# iostr710 register map
Registers are 16-bit, access not given, no defined reset value unless marked. A register's access mark holds for its fields unless they carry their own. Addresses are absolute; registers are grouped by the start of their names; [hi:lo] are bit positions; {n}, {i} and the like mark numbered series.

## I2C0
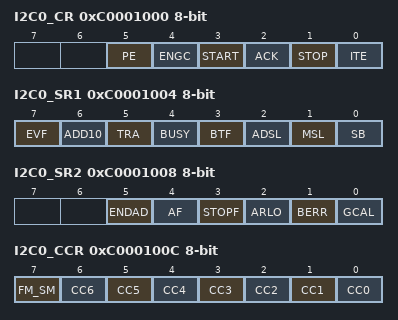
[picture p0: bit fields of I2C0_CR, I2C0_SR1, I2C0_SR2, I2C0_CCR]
0xC0001000 I2C0_CR 8-bit
  [5] PE, [4] ENGC, [3] START, [2] ACK, [1] STOP, [0] ITE
0xC0001004 I2C0_SR1 8-bit
  [7] EVF, [6] ADD10, [5] TRA, [4] BUSY, [3] BTF, [2] ADSL, [1] MSL, [0] SB
0xC0001008 I2C0_SR2 8-bit
  [5] ENDAD, [4] AF, [3] STOPF, [2] ARLO, [1] BERR, [0] GCAL
0xC000100C I2C0_CCR 8-bit
  [7] FM_SM, [n] CC{n} (n=0..6)
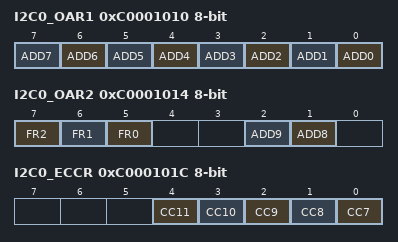
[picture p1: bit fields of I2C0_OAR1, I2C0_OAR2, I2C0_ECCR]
0xC0001010 I2C0_OAR1 8-bit
  [n] ADD{n} (n=0..7)
0xC0001014 I2C0_OAR2 8-bit
  [7] FR2, [6] FR1, [5] FR0, [2] ADD9, [1] ADD8
0xC0001018 I2C0_DR 8-bit
0xC000101C I2C0_ECCR 8-bit
  [n-7] CC{n} (n=7..11)

## I2C1
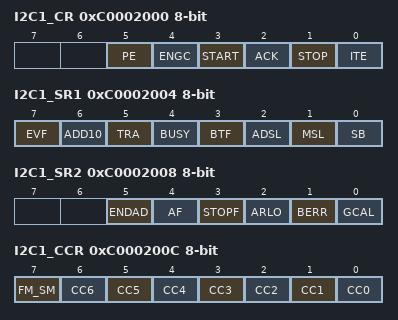
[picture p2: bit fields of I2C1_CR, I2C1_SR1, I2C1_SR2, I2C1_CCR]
0xC0002000 I2C1_CR 8-bit
  [5] PE, [4] ENGC, [3] START, [2] ACK, [1] STOP, [0] ITE
0xC0002004 I2C1_SR1 8-bit
  [7] EVF, [6] ADD10, [5] TRA, [4] BUSY, [3] BTF, [2] ADSL, [1] MSL, [0] SB
0xC0002008 I2C1_SR2 8-bit
  [5] ENDAD, [4] AF, [3] STOPF, [2] ARLO, [1] BERR, [0] GCAL
0xC000200C I2C1_CCR 8-bit
  [7] FM_SM, [n] CC{n} (n=0..6)
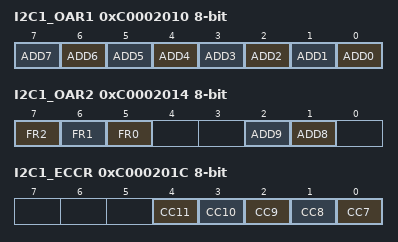
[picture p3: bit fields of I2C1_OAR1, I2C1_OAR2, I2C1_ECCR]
0xC0002010 I2C1_OAR1 8-bit
  [n] ADD{n} (n=0..7)
0xC0002014 I2C1_OAR2 8-bit
  [7] FR2, [6] FR1, [5] FR0, [2] ADD9, [1] ADD8
0xC0002018 I2C1_DR 8-bit
0xC000201C I2C1_ECCR 8-bit
  [n-7] CC{n} (n=7..11)

## BSPI0
0xC000A000 BSPI0_RXR
  [15:8] RX_8BITS
0xC000A004 BSPI0_TXR
  [15:8] TX_8BITS
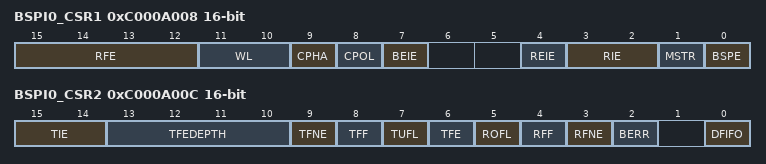
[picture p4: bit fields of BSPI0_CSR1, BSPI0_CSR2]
0xC000A008 BSPI0_CSR1
  [15:12] RFE, [11:10] WL, [9] CPHA, [8] CPOL, [7] BEIE, [4] REIE, [3:2] RIE, [1] MSTR, [0] BSPE
0xC000A00C BSPI0_CSR2
  [15:14] TIE, [13:10] TFEDEPTH, [9] TFNE, [8] TFF, [7] TUFL, [6] TFE, [5] ROFL, [4] RFF, [3] RFNE, [2] BERR, [0] DFIFO
0xC000A010 BSPI0_CLK 8-bit

## BSPI1
0xC000B000 BSPI1_RXR
  [15:8] RX_8BITS
0xC000B004 BSPI1_TXR
  [15:8] TX_8BITS
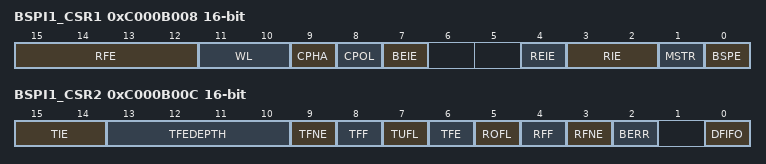
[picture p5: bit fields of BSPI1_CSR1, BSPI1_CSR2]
0xC000B008 BSPI1_CSR1
  [15:12] RFE, [11:10] WL, [9] CPHA, [8] CPOL, [7] BEIE, [4] REIE, [3:2] RIE, [1] MSTR, [0] BSPE
0xC000B00C BSPI1_CSR2
  [15:14] TIE, [13:10] TFEDEPTH, [9] TFNE, [8] TFF, [7] TUFL, [6] TFE, [5] ROFL, [4] RFF, [3] RFNE, [2] BERR, [0] DFIFO
0xC000B010 BSPI1_CLK 8-bit

## UART0
0xC0004000 UART0_BR
0xC0004004 UART0_TXBUFR
  [8:0] TX
0xC0004008 UART0_RXBUFR
  [9:0] RX
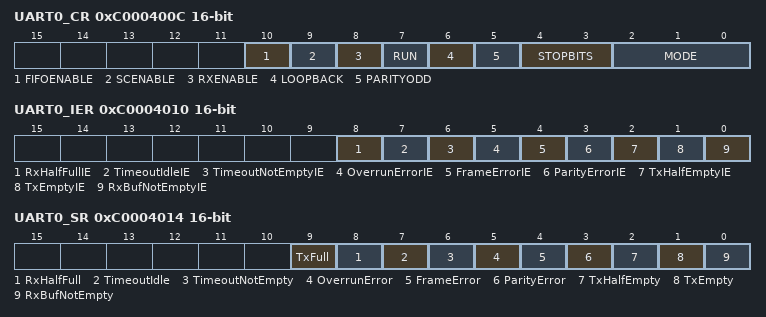
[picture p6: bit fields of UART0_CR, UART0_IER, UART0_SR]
0xC000400C UART0_CR
  [10] FIFOENABLE, [9] SCENABLE, [8] RXENABLE, [7] RUN, [6] LOOPBACK, [5] PARITYODD, [4:3] STOPBITS, [2:0] MODE
0xC0004010 UART0_IER
  [8] RxHalfFullIE, [7] TimeoutIdleIE, [6] TimeoutNotEmptyIE, [5] OverrunErrorIE, [4] FrameErrorIE, [3] ParityErrorIE, [2] TxHalfEmptyIE, [1] TxEmptyIE, [0] RxBufNotEmptyIE
0xC0004014 UART0_SR
  [9] TxFull, [8] RxHalfFull, [7] TimeoutIdle, [6] TimeoutNotEmpty, [5] OverrunError, [4] FrameError, [3] ParityError, [2] TxHalfEmpty, [1] TxEmpty, [0] RxBufNotEmpty
0xC0004018 UART0_GTR
  [7:0] GUARDTIME
0xC000401C UART0_TOR
  [7:0] TIMEOUT
0xC0004020 UART0_TXRSTR
0xC0004024 UART0_RXRSTR

## UART1
0xC0005000 UART1_BR
0xC0005004 UART1_TXBUFR
  [8:0] TX
0xC0005008 UART1_RXBUFR
  [9:0] RX
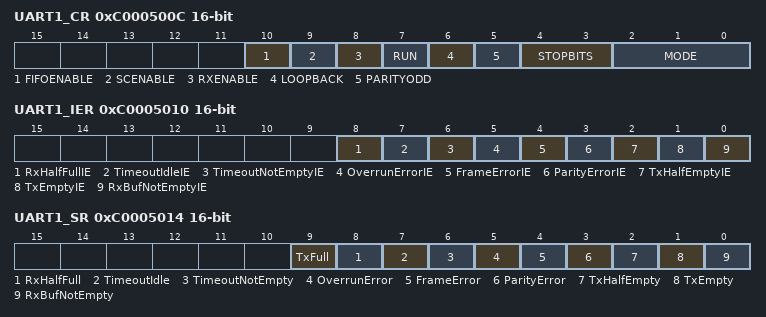
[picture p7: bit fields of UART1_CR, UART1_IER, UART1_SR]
0xC000500C UART1_CR
  [10] FIFOENABLE, [9] SCENABLE, [8] RXENABLE, [7] RUN, [6] LOOPBACK, [5] PARITYODD, [4:3] STOPBITS, [2:0] MODE
0xC0005010 UART1_IER
  [8] RxHalfFullIE, [7] TimeoutIdleIE, [6] TimeoutNotEmptyIE, [5] OverrunErrorIE, [4] FrameErrorIE, [3] ParityErrorIE, [2] TxHalfEmptyIE, [1] TxEmptyIE, [0] RxBufNotEmptyIE
0xC0005014 UART1_SR
  [9] TxFull, [8] RxHalfFull, [7] TimeoutIdle, [6] TimeoutNotEmpty, [5] OverrunError, [4] FrameError, [3] ParityError, [2] TxHalfEmpty, [1] TxEmpty, [0] RxBufNotEmpty
0xC0005018 UART1_GTR
  [7:0] GUARDTIME
0xC000501C UART1_TOR
  [7:0] TIMEOUT
0xC0005020 UART1_TXRSTR
0xC0005024 UART1_RXRSTR

## SC
0xC0005040 SC_CLKVAL
  [4:0] SCCLKVAL
0xC0005044 SC_CLKCON
  [0] EN

## UART2
0xC0006000 UART2_BR
0xC0006004 UART2_TXBUFR
  [8:0] TX
0xC0006008 UART2_RXBUFR
  [9:0] RX
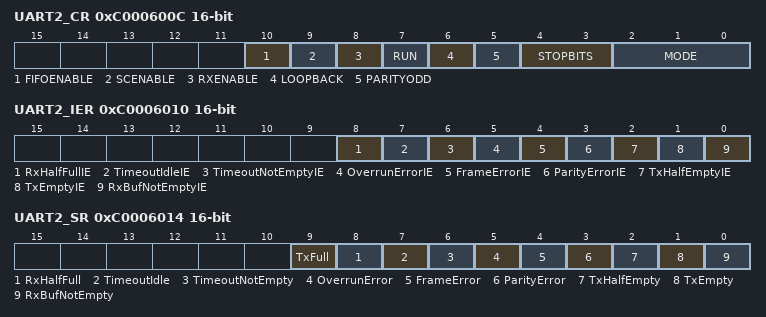
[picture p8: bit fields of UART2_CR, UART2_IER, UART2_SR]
0xC000600C UART2_CR
  [10] FIFOENABLE, [9] SCENABLE, [8] RXENABLE, [7] RUN, [6] LOOPBACK, [5] PARITYODD, [4:3] STOPBITS, [2:0] MODE
0xC0006010 UART2_IER
  [8] RxHalfFullIE, [7] TimeoutIdleIE, [6] TimeoutNotEmptyIE, [5] OverrunErrorIE, [4] FrameErrorIE, [3] ParityErrorIE, [2] TxHalfEmptyIE, [1] TxEmptyIE, [0] RxBufNotEmptyIE
0xC0006014 UART2_SR
  [9] TxFull, [8] RxHalfFull, [7] TimeoutIdle, [6] TimeoutNotEmpty, [5] OverrunError, [4] FrameError, [3] ParityError, [2] TxHalfEmpty, [1] TxEmpty, [0] RxBufNotEmpty
0xC0006018 UART2_GTR
  [7:0] GUARDTIME
0xC000601C UART2_TOR
  [7:0] TIMEOUT
0xC0006020 UART2_TXRSTR
0xC0006024 UART2_RXRSTR

## UART3
0xC0007000 UART3_BR
0xC0007004 UART3_TXBUFR
  [8:0] TX
0xC0007008 UART3_RXBUFR
  [9:0] RX
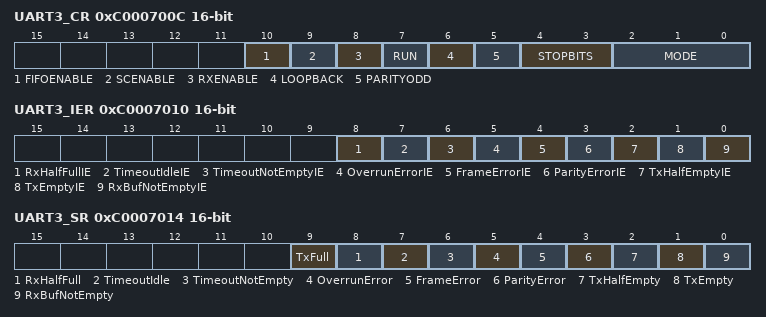
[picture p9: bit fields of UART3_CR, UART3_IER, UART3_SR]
0xC000700C UART3_CR
  [10] FIFOENABLE, [9] SCENABLE, [8] RXENABLE, [7] RUN, [6] LOOPBACK, [5] PARITYODD, [4:3] STOPBITS, [2:0] MODE
0xC0007010 UART3_IER
  [8] RxHalfFullIE, [7] TimeoutIdleIE, [6] TimeoutNotEmptyIE, [5] OverrunErrorIE, [4] FrameErrorIE, [3] ParityErrorIE, [2] TxHalfEmptyIE, [1] TxEmptyIE, [0] RxBufNotEmptyIE
0xC0007014 UART3_SR
  [9] TxFull, [8] RxHalfFull, [7] TimeoutIdle, [6] TimeoutNotEmpty, [5] OverrunError, [4] FrameError, [3] ParityError, [2] TxHalfEmpty, [1] TxEmpty, [0] RxBufNotEmpty
0xC0007018 UART3_GTR
  [7:0] GUARDTIME
0xC000701C UART3_TOR
  [7:0] TIMEOUT
0xC0007020 UART3_TXRSTR
0xC0007024 UART3_RXRSTR

## USB
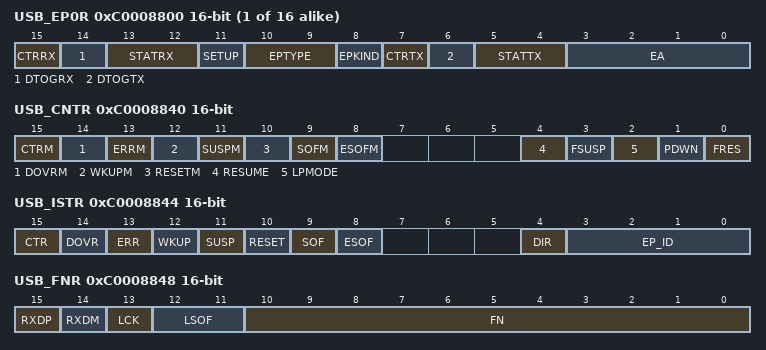
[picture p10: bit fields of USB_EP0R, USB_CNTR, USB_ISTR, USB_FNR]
{0xC0008800+4i} USB_EP{i}R (i=0..15)
  [15] CTRRX, [14] DTOGRX, [13:12] STATRX, [11] SETUP, [10:9] EPTYPE, [8] EPKIND, [7] CTRTX, [6] DTOGTX, [5:4] STATTX, [3:0] EA
0xC0008840 USB_CNTR
  [15] CTRM, [14] DOVRM, [13] ERRM, [12] WKUPM, [11] SUSPM, [10] RESETM, [9] SOFM, [8] ESOFM, [4] RESUME, [3] FSUSP, [2] LPMODE, [1] PDWN, [0] FRES
0xC0008844 USB_ISTR
  [15] CTR, [14] DOVR, [13] ERR, [12] WKUP, [11] SUSP, [10] RESET, [9] SOF, [8] ESOF, [4] DIR, [3:0] EP_ID
0xC0008848 USB_FNR
  [15] RXDP, [14] RXDM, [13] LCK, [12:11] LSOF, [10:0] FN
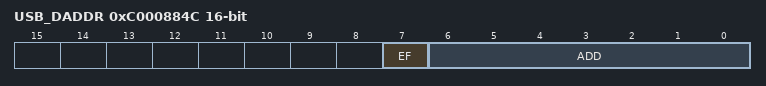
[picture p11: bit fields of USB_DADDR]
0xC000884C USB_DADDR
  [7] EF, [6:0] ADD
0xC0008850 USB_BTABLE

## HDLC
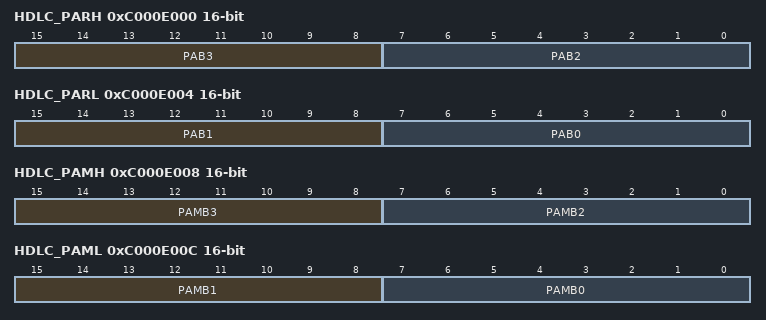
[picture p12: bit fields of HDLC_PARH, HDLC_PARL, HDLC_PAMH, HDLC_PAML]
0xC000E000 HDLC_PARH
  [15:8] PAB3, [7:0] PAB2
0xC000E004 HDLC_PARL
  [15:8] PAB1, [7:0] PAB0
0xC000E008 HDLC_PAMH
  [15:8] PAMB3, [7:0] PAMB2
0xC000E00C HDLC_PAML
  [15:8] PAMB1, [7:0] PAMB0
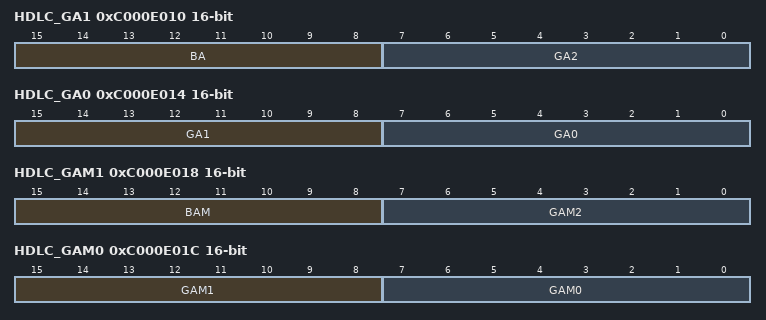
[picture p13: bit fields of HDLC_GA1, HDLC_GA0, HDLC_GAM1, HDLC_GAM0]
0xC000E010 HDLC_GA1
  [15:8] BA, [7:0] GA2
0xC000E014 HDLC_GA0
  [15:8] GA1, [7:0] GA0
0xC000E018 HDLC_GAM1
  [15:8] BAM, [7:0] GAM2
0xC000E01C HDLC_GAM0
  [15:8] GAM1, [7:0] GAM0
0xC000E020 HDLC_PRES
0xC000E024 HDLC_POSS
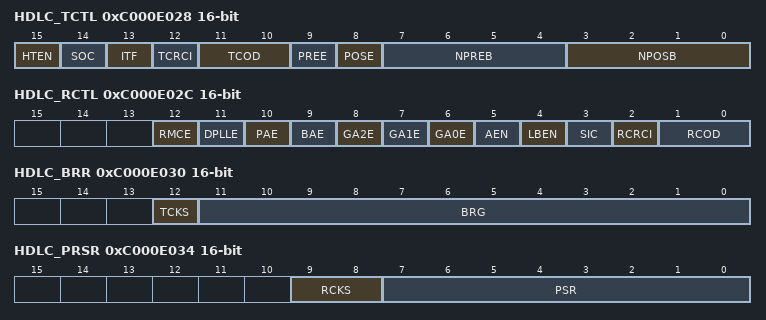
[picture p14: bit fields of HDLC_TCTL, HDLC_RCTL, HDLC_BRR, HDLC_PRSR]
0xC000E028 HDLC_TCTL
  [15] HTEN, [14] SOC, [13] ITF, [12] TCRCI, [11:10] TCOD, [9] PREE, [8] POSE, [7:4] NPREB, [3:0] NPOSB
0xC000E02C HDLC_RCTL
  [12] RMCE, [11] DPLLE, [10] PAE, [9] BAE, [8] GA2E, [7] GA1E, [6] GA0E, [5] AEN, [4] LBEN, [3] SIC, [2] RCRCI, [1:0] RCOD
0xC000E030 HDLC_BRR
  [12] TCKS, [11:0] BRG
0xC000E034 HDLC_PRSR
  [9:8] RCKS, [7:0] PSR
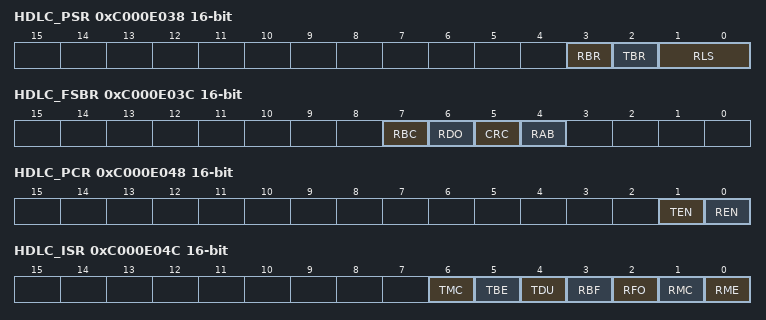
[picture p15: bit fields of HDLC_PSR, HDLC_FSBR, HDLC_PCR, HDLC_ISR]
0xC000E038 HDLC_PSR
  [3] RBR, [2] TBR, [1:0] RLS
0xC000E03C HDLC_FSBR
  [7] RBC, [6] RDO, [5] CRC, [4] RAB
0xC000E040 HDLC_TFBCR
0xC000E044 HDLC_RFBCR
0xC000E048 HDLC_PCR
  [1] TEN, [0] REN
0xC000E04C HDLC_ISR
  [6] TMC, [5] TBE, [4] TDU, [3] RBF, [2] RFO, [1] RMC, [0] RME
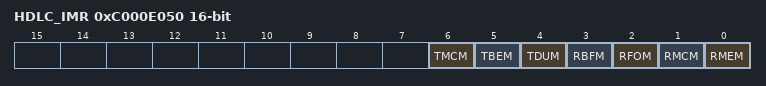
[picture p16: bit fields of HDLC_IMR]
0xC000E050 HDLC_IMR
  [6] TMCM, [5] TBEM, [4] TDUM, [3] RBFM, [2] RFOM, [1] RMCM, [0] RMEM

## ADC
{0xE0007000+8i} ADC_DATA{i} (i=0..3)
  [15:4] DATA
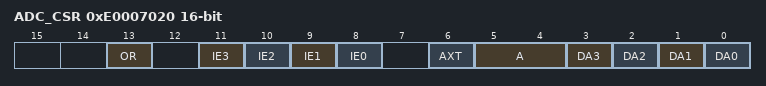
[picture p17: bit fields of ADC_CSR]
0xE0007020 ADC_CSR
  [13] OR, [n+8] IE{n} (n=0..3), [6] AXT, [5:4] A, [n] DA{n} (n=0..3)
0xE0007030 ADC_CPR
  [11:0] PRESC

## APB1
0xC0000010 APB1_CKDIS 32-bit
  [14:0] PCKDIS
0xC0000014 APB1_SWRES 32-bit
  [13] HDLC, [10] BSPI1, [9] BSPI0, [8] CAN, [7] USB, [6] UART3, [5] UART2, [4] UART1PLUSCARD, [3] UART0, [1] I2C1, [0] I2C0

## APB2
0xE0000010 APB2_CKDIS 32-bit
  [14:0] PCKDIS
0xE0000014 APB2_SWRES 32-bit
  [14] EIC, [13] WDG, [12] RTC, [n+8] TIMER{n} (n=0..3), [7] CKOUT, [6] ADC, [4] IOPORT2, [3] IOPORT1, [2] IOPORT0, [0] XTI
